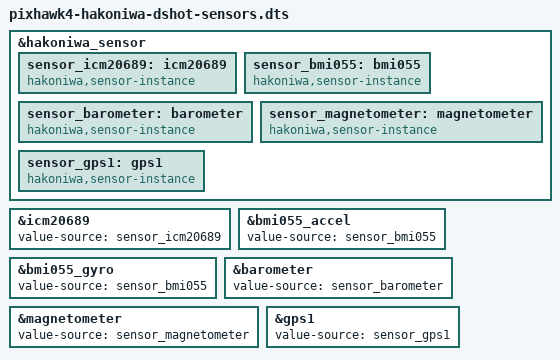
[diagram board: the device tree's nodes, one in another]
/* SPDX-License-Identifier: MIT */

/*
 * Pixhawk 4 with Hakoniwa and DShot, each sensor chip fed by its own sensor
 * instance of the sensor host (docs/sensor-host.md). An instance's node name
 * is its name in the run's HAKO_SENSOR_DEVICE_SENSORS, which gives its type,
 * its adapter and its mount. The BMI055's accelerometer and gyro are one chip
 * and share one instance. The motors stay on the sensor device. An instance
 * has no tick of its own, so the chips drop the tick-before marker of the
 * Hakoniwa board.
 */

#include "pixhawk4-hakoniwa-dshot.dts"

&hakoniwa_sensor {
	sensor_icm20689: icm20689 {
		compatible = "hakoniwa,sensor-instance";
	};
	sensor_bmi055: bmi055 {
		compatible = "hakoniwa,sensor-instance";
	};
	sensor_barometer: barometer {
		compatible = "hakoniwa,sensor-instance";
	};
	sensor_magnetometer: magnetometer {
		compatible = "hakoniwa,sensor-instance";
	};
	sensor_gps1: gps1 {
		compatible = "hakoniwa,sensor-instance";
	};
};

&icm20689 {
	value-source = <&sensor_icm20689>;
	/delete-property/ athrill,tick-before-value-source;
};
&bmi055_accel {
	value-source = <&sensor_bmi055>;
	/delete-property/ athrill,tick-before-value-source;
};
&bmi055_gyro {
	value-source = <&sensor_bmi055>;
	/delete-property/ athrill,tick-before-value-source;
};
&barometer {
	value-source = <&sensor_barometer>;
	/delete-property/ athrill,tick-before-value-source;
};
&magnetometer {
	value-source = <&sensor_magnetometer>;
	/delete-property/ athrill,tick-before-value-source;
};
&gps1 {
	value-source = <&sensor_gps1>;
	/delete-property/ athrill,tick-before-value-source;
};
